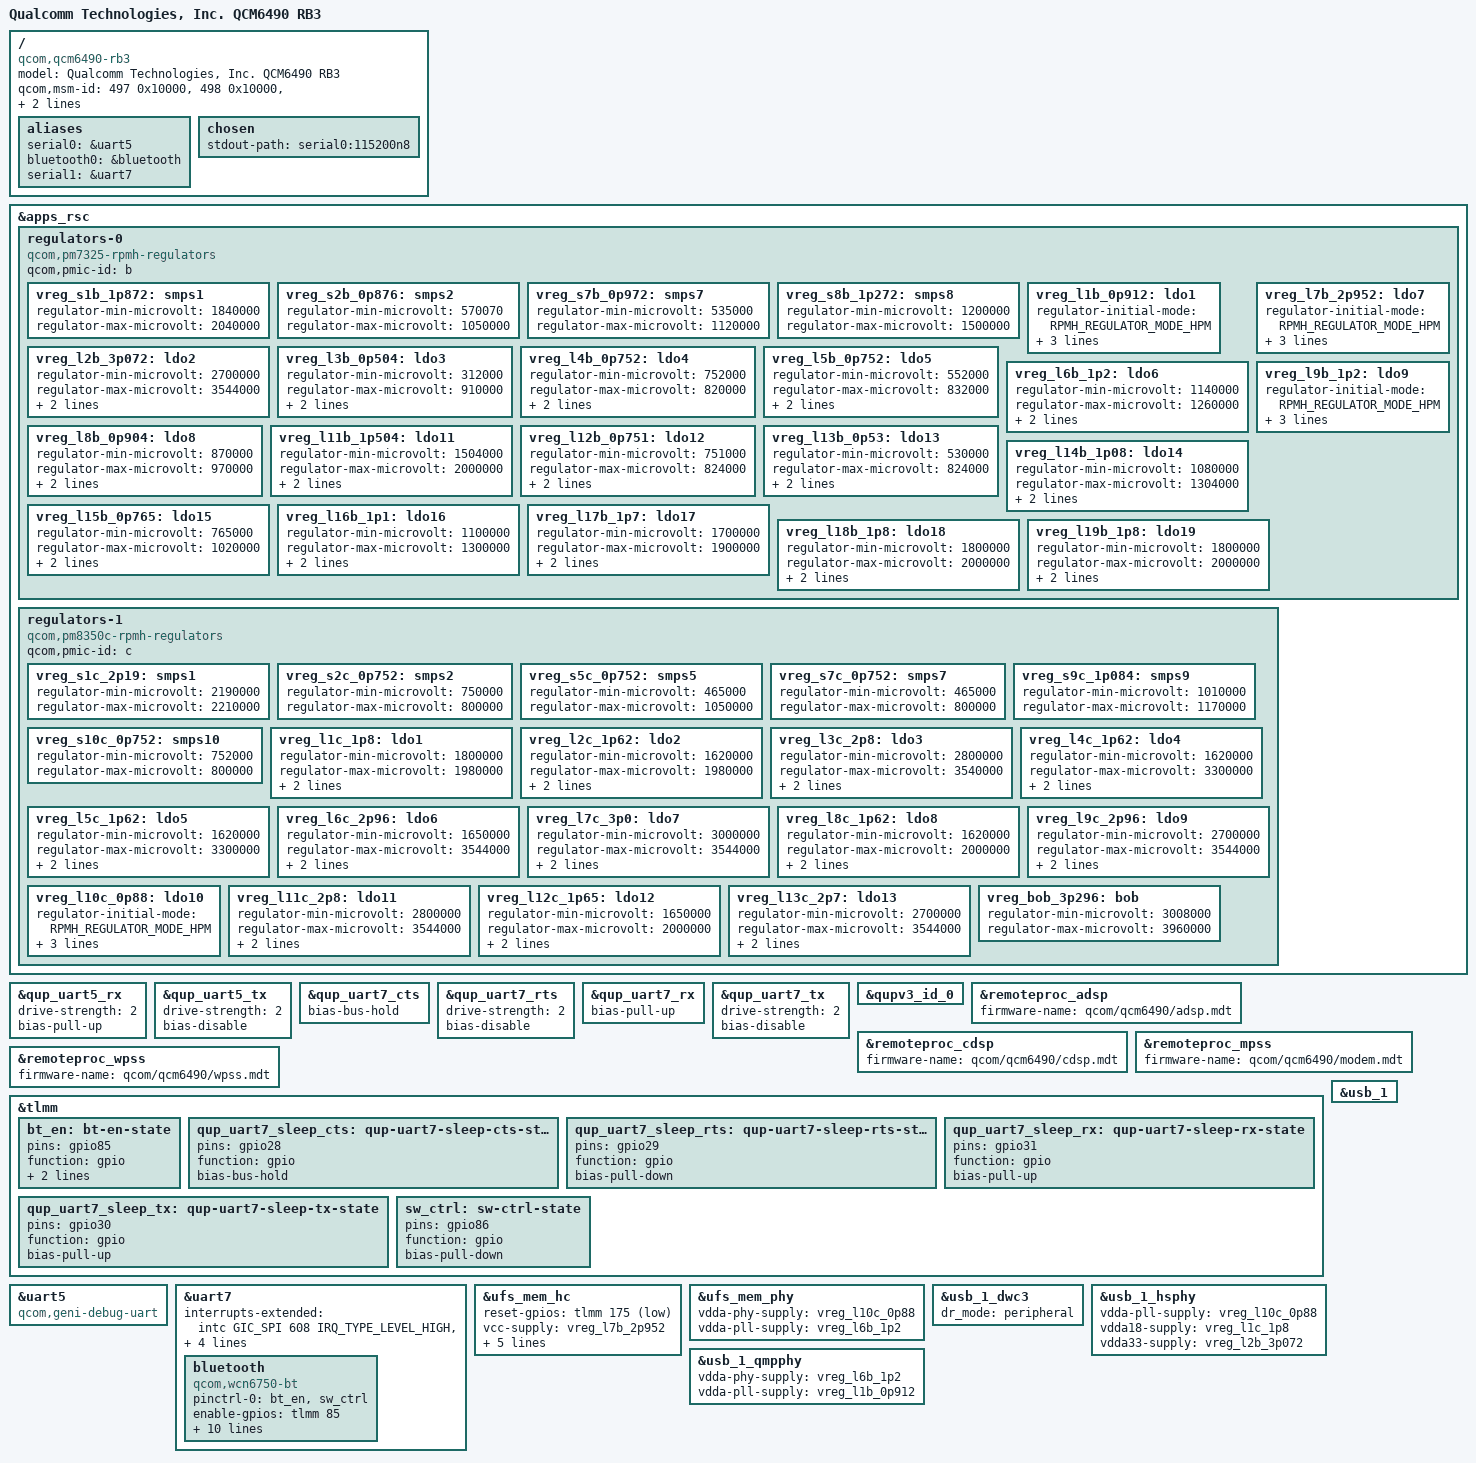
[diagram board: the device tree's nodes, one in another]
// SPDX-License-Identifier: BSD-3-Clause
/*
 * Copyright (c) 2023 Qualcomm Innovation Center, Inc. All rights reserved.
 */

/dts-v1/;

/* PM7250B is configured to use SID8/9 */
#define PM7250B_SID 8
#define PM7250B_SID1 9

#include <dt-bindings/pinctrl/qcom,pmic-gpio.h>
#include <dt-bindings/regulator/qcom,rpmh-regulator.h>
#include "qcm6490.dtsi"
#include "pm7250b.dtsi"
#include "pm7325.dtsi"
#include "pm8350c.dtsi"
#include "pmk8350.dtsi"

/ {
	model = "Qualcomm Technologies, Inc. QCM6490 RB3";
	compatible = "qcom,qcm6490-rb3", "qcom,qcm6490";

	/* This will be deprecated soon */
	qcom,msm-id = <497 0x10000>, <498 0x10000>, <475 0x10000>, <515 0x10000>;
	qcom,board-id = <32 1>;

	aliases {
		serial0 = &uart5;
		bluetooth0 = &bluetooth;
		serial1 = &uart7;
	};

	chosen {
		stdout-path = "serial0:115200n8";
	};
};

&apps_rsc {
	regulators-0 {
		compatible = "qcom,pm7325-rpmh-regulators";
		qcom,pmic-id = "b";

		vreg_s1b_1p872: smps1 {
			regulator-min-microvolt = <1840000>;
			regulator-max-microvolt = <2040000>;
		};

		vreg_s2b_0p876: smps2 {
			regulator-min-microvolt = <570070>;
			regulator-max-microvolt = <1050000>;
		};

		vreg_s7b_0p972: smps7 {
			regulator-min-microvolt = <535000>;
			regulator-max-microvolt = <1120000>;
		};

		vreg_s8b_1p272: smps8 {
			regulator-min-microvolt = <1200000>;
			regulator-max-microvolt = <1500000>;
		};

		vreg_l1b_0p912: ldo1 {
			regulator-min-microvolt = <825000>;
			regulator-max-microvolt = <925000>;
			regulator-initial-mode = <RPMH_REGULATOR_MODE_HPM>;
		};

		vreg_l2b_3p072: ldo2 {
			regulator-min-microvolt = <2700000>;
			regulator-max-microvolt = <3544000>;
			regulator-initial-mode = <RPMH_REGULATOR_MODE_HPM>;
		};

		vreg_l3b_0p504: ldo3 {
			regulator-min-microvolt = <312000>;
			regulator-max-microvolt = <910000>;
			regulator-initial-mode = <RPMH_REGULATOR_MODE_HPM>;
		};

		vreg_l4b_0p752: ldo4 {
			regulator-min-microvolt = <752000>;
			regulator-max-microvolt = <820000>;
			regulator-initial-mode = <RPMH_REGULATOR_MODE_HPM>;
		};

		vreg_l5b_0p752: ldo5 {
			regulator-min-microvolt = <552000>;
			regulator-max-microvolt = <832000>;
			regulator-initial-mode = <RPMH_REGULATOR_MODE_HPM>;
		};

		vreg_l6b_1p2: ldo6 {
			regulator-min-microvolt = <1140000>;
			regulator-max-microvolt = <1260000>;
			regulator-initial-mode = <RPMH_REGULATOR_MODE_HPM>;
		};

		vreg_l7b_2p952: ldo7 {
			regulator-min-microvolt = <2400000>;
			regulator-max-microvolt = <3544000>;
			regulator-initial-mode = <RPMH_REGULATOR_MODE_HPM>;
		};

		vreg_l8b_0p904: ldo8 {
			regulator-min-microvolt = <870000>;
			regulator-max-microvolt = <970000>;
			regulator-initial-mode = <RPMH_REGULATOR_MODE_HPM>;
		};

		vreg_l9b_1p2: ldo9 {
			regulator-min-microvolt = <1200000>;
			regulator-max-microvolt = <1304000>;
			regulator-initial-mode = <RPMH_REGULATOR_MODE_HPM>;
		};

		vreg_l11b_1p504: ldo11 {
			regulator-min-microvolt = <1504000>;
			regulator-max-microvolt = <2000000>;
			regulator-initial-mode = <RPMH_REGULATOR_MODE_HPM>;
		};

		vreg_l12b_0p751: ldo12 {
			regulator-min-microvolt = <751000>;
			regulator-max-microvolt = <824000>;
			regulator-initial-mode = <RPMH_REGULATOR_MODE_HPM>;
		};

		vreg_l13b_0p53: ldo13 {
			regulator-min-microvolt = <530000>;
			regulator-max-microvolt = <824000>;
			regulator-initial-mode = <RPMH_REGULATOR_MODE_HPM>;
		};

		vreg_l14b_1p08: ldo14 {
			regulator-min-microvolt = <1080000>;
			regulator-max-microvolt = <1304000>;
			regulator-initial-mode = <RPMH_REGULATOR_MODE_HPM>;
		};

		vreg_l15b_0p765: ldo15 {
			regulator-min-microvolt = <765000>;
			regulator-max-microvolt = <1020000>;
			regulator-initial-mode = <RPMH_REGULATOR_MODE_HPM>;
		};

		vreg_l16b_1p1: ldo16 {
			regulator-min-microvolt = <1100000>;
			regulator-max-microvolt = <1300000>;
			regulator-initial-mode = <RPMH_REGULATOR_MODE_HPM>;
		};

		vreg_l17b_1p7: ldo17 {
			regulator-min-microvolt = <1700000>;
			regulator-max-microvolt = <1900000>;
			regulator-initial-mode = <RPMH_REGULATOR_MODE_HPM>;
		};

		vreg_l18b_1p8: ldo18 {
			regulator-min-microvolt = <1800000>;
			regulator-max-microvolt = <2000000>;
			regulator-initial-mode = <RPMH_REGULATOR_MODE_HPM>;
		};

		vreg_l19b_1p8: ldo19 {
			regulator-min-microvolt = <1800000>;
			regulator-max-microvolt = <2000000>;
			regulator-initial-mode = <RPMH_REGULATOR_MODE_HPM>;
		};
	};

	regulators-1 {
		compatible = "qcom,pm8350c-rpmh-regulators";
		qcom,pmic-id = "c";

		vreg_s1c_2p19: smps1 {
			regulator-min-microvolt = <2190000>;
			regulator-max-microvolt = <2210000>;
		};

		vreg_s2c_0p752: smps2 {
			regulator-min-microvolt = <750000>;
			regulator-max-microvolt = <800000>;
		};

		vreg_s5c_0p752: smps5 {
			regulator-min-microvolt = <465000>;
			regulator-max-microvolt = <1050000>;
		};

		vreg_s7c_0p752: smps7 {
			regulator-min-microvolt = <465000>;
			regulator-max-microvolt = <800000>;
		};

		vreg_s9c_1p084: smps9 {
			regulator-min-microvolt = <1010000>;
			regulator-max-microvolt = <1170000>;
		};

		vreg_s10c_0p752:smps10 {
			regulator-min-microvolt = <752000>;
			regulator-max-microvolt = <800000>;
		};

		vreg_l1c_1p8: ldo1 {
			regulator-min-microvolt = <1800000>;
			regulator-max-microvolt = <1980000>;
			regulator-initial-mode = <RPMH_REGULATOR_MODE_HPM>;
		};

		vreg_l2c_1p62: ldo2 {
			regulator-min-microvolt = <1620000>;
			regulator-max-microvolt = <1980000>;
			regulator-initial-mode = <RPMH_REGULATOR_MODE_HPM>;
		};

		vreg_l3c_2p8: ldo3 {
			regulator-min-microvolt = <2800000>;
			regulator-max-microvolt = <3540000>;
			regulator-initial-mode = <RPMH_REGULATOR_MODE_HPM>;
		};

		vreg_l4c_1p62: ldo4 {
			regulator-min-microvolt = <1620000>;
			regulator-max-microvolt = <3300000>;
			regulator-initial-mode = <RPMH_REGULATOR_MODE_HPM>;
		};

		vreg_l5c_1p62: ldo5 {
			regulator-min-microvolt = <1620000>;
			regulator-max-microvolt = <3300000>;
			regulator-initial-mode = <RPMH_REGULATOR_MODE_HPM>;
		};

		vreg_l6c_2p96: ldo6 {
			regulator-min-microvolt = <1650000>;
			regulator-max-microvolt = <3544000>;
			regulator-initial-mode = <RPMH_REGULATOR_MODE_HPM>;
		};

		vreg_l7c_3p0: ldo7 {
			regulator-min-microvolt = <3000000>;
			regulator-max-microvolt = <3544000>;
			regulator-initial-mode = <RPMH_REGULATOR_MODE_HPM>;
		};

		vreg_l8c_1p62: ldo8 {
			regulator-min-microvolt = <1620000>;
			regulator-max-microvolt = <2000000>;
			regulator-initial-mode = <RPMH_REGULATOR_MODE_HPM>;
		};

		vreg_l9c_2p96: ldo9 {
			regulator-min-microvolt = <2700000>;
			regulator-max-microvolt = <3544000>;
			regulator-initial-mode = <RPMH_REGULATOR_MODE_HPM>;
		};

		vreg_l10c_0p88:ldo10 {
			regulator-min-microvolt = <720000>;
			regulator-max-microvolt = <1050000>;
			regulator-initial-mode = <RPMH_REGULATOR_MODE_HPM>;
		};

		vreg_l11c_2p8: ldo11 {
			regulator-min-microvolt = <2800000>;
			regulator-max-microvolt = <3544000>;
			regulator-initial-mode = <RPMH_REGULATOR_MODE_HPM>;
		};

		vreg_l12c_1p65: ldo12 {
			regulator-min-microvolt = <1650000>;
			regulator-max-microvolt = <2000000>;
			regulator-initial-mode = <RPMH_REGULATOR_MODE_HPM>;
		};

		vreg_l13c_2p7: ldo13 {
			regulator-min-microvolt = <2700000>;
			regulator-max-microvolt = <3544000>;
			regulator-initial-mode = <RPMH_REGULATOR_MODE_HPM>;
		};

		vreg_bob_3p296: bob {
			regulator-min-microvolt = <3008000>;
			regulator-max-microvolt = <3960000>;
		};
	};
};

&qup_uart5_rx {
	drive-strength = <2>;
	bias-pull-up;
};

&qup_uart5_tx {
	drive-strength = <2>;
	bias-disable;
};

&qup_uart7_cts {
	/*
	 * Configure a bias-bus-hold on CTS to lower power
	 * usage when Bluetooth is turned off. Bus hold will
	 * maintain a low power state regardless of whether
	 * the Bluetooth module drives the pin in either
	 * direction or leaves the pin fully unpowered.
	 */
	bias-bus-hold;
};

&qup_uart7_rts {
	/* We'll drive RTS, so no pull */
	drive-strength = <2>;
	bias-disable;
};

&qup_uart7_rx {
	/*
	 * Configure a pull-up on RX. This is needed to avoid
	 * garbage data when the TX pin of the Bluetooth module is
	 * in tri-state (module powered off or not driving the
	 * signal yet).
	 */
	bias-pull-up;
};

&qup_uart7_tx {
	/* We'll drive TX, so no pull */
	drive-strength = <2>;
	bias-disable;
};

&qupv3_id_0 {
	status = "okay";
};

&remoteproc_adsp {
	firmware-name = "qcom/qcm6490/adsp.mdt";
	status = "okay";
};

&remoteproc_cdsp {
	firmware-name = "qcom/qcm6490/cdsp.mdt";
	status = "okay";
};

&remoteproc_mpss {
	firmware-name = "qcom/qcm6490/modem.mdt";
	status = "okay";
};

&remoteproc_wpss {
	firmware-name = "qcom/qcm6490/wpss.mdt";
	status = "okay";
};

&tlmm {
	bt_en: bt-en-state {
		pins = "gpio85";
		function = "gpio";
		output-low;
		bias-disable;
	};

	qup_uart7_sleep_cts: qup-uart7-sleep-cts-state {
		pins = "gpio28";
		function = "gpio";
		/*
		 * Configure a bias-bus-hold on CTS to lower power
		 * usage when Bluetooth is turned off. Bus hold will
		 * maintain a low power state regardless of whether
		 * the Bluetooth module drives the pin in either
		 * direction or leaves the pin fully unpowered.
		 */
		bias-bus-hold;
	};

	qup_uart7_sleep_rts: qup-uart7-sleep-rts-state {
		pins = "gpio29";
		function = "gpio";
		/*
		 * Configure pull-down on RTS. As RTS is active low
		 * signal, pull it low to indicate the BT SoC that it
		 * can wakeup the system anytime from suspend state by
		 * pulling RX low (by sending wakeup bytes).
		 */
		bias-pull-down;
	};

	qup_uart7_sleep_rx: qup-uart7-sleep-rx-state {
		pins = "gpio31";
		function = "gpio";
		/*
		 * Configure a pull-up on RX. This is needed to avoid
		 * garbage data when the TX pin of the Bluetooth module
		 * is floating which may cause spurious wakeups.
		 */
		bias-pull-up;
	};

	qup_uart7_sleep_tx: qup-uart7-sleep-tx-state {
		pins = "gpio30";
		function = "gpio";
		/*
		 * Configure pull-up on TX when it isn't actively driven
		 * to prevent BT SoC from receiving garbage during sleep.
		 */
		bias-pull-up;
	};

	sw_ctrl: sw-ctrl-state {
		pins = "gpio86";
		function = "gpio";
		bias-pull-down;
	};
};

&uart5 {
	compatible = "qcom,geni-debug-uart";
	status = "okay";
};

&uart7 {
	status = "okay";
	/delete-property/interrupts;
	interrupts-extended = <&intc GIC_SPI 608 IRQ_TYPE_LEVEL_HIGH>,
				<&tlmm 31 IRQ_TYPE_EDGE_FALLING>;
	pinctrl-names = "default", "sleep";
	pinctrl-1 = <&qup_uart7_sleep_cts>, <&qup_uart7_sleep_rts>,
			<&qup_uart7_sleep_tx>, <&qup_uart7_sleep_rx>;

	bluetooth: bluetooth {
		compatible = "qcom,wcn6750-bt";
		pinctrl-names = "default";
		pinctrl-0 = <&bt_en>, <&sw_ctrl>;
		enable-gpios = <&tlmm 85 GPIO_ACTIVE_HIGH>;
		swctrl-gpios = <&tlmm 86 GPIO_ACTIVE_HIGH>;
		vddaon-supply = <&vreg_s7b_0p972>;
		vddbtcxmx-supply = <&vreg_s7b_0p972>;
		vddrfacmn-supply = <&vreg_s7b_0p972>;
		vddrfa0p8-supply = <&vreg_s7b_0p972>;
		vddrfa1p7-supply = <&vreg_s1b_1p872>;
		vddrfa1p2-supply = <&vreg_s8b_1p272>;
		vddrfa2p2-supply = <&vreg_s1c_2p19>;
		vddasd-supply = <&vreg_l11c_2p8>;
		max-speed = <3200000>;
	};
};

&ufs_mem_hc {
	reset-gpios = <&tlmm 175 GPIO_ACTIVE_LOW>;
	vcc-supply = <&vreg_l7b_2p952>;
	vcc-max-microamp = <800000>;
	vccq-supply = <&vreg_l9b_1p2>;
	vccq-max-microamp = <900000>;
	vccq2-supply = <&vreg_l9b_1p2>;
	vccq2-max-microamp = <900000>;

	status = "okay";
};

&ufs_mem_phy {
	vdda-phy-supply = <&vreg_l10c_0p88>;
	vdda-pll-supply = <&vreg_l6b_1p2>;

	status = "okay";
};

&usb_1 {
	status = "okay";
};

&usb_1_dwc3 {
	dr_mode = "peripheral";
};

&usb_1_hsphy {
	vdda-pll-supply = <&vreg_l10c_0p88>;
	vdda18-supply = <&vreg_l1c_1p8>;
	vdda33-supply = <&vreg_l2b_3p072>;

	status = "okay";
};

&usb_1_qmpphy {
	vdda-phy-supply = <&vreg_l6b_1p2>;
	vdda-pll-supply = <&vreg_l1b_0p912>;

	status = "okay";
};

&vreg_l1b_0p912 {
	/delete-property/regulator-min-microvolt;
	/delete-property/regulator-max-microvolt;
	regulator-allow-set-load;
	regulator-allowed-modes = <RPMH_REGULATOR_MODE_LPM RPMH_REGULATOR_MODE_HPM>;
};

&vreg_l7b_2p952 {
	/delete-property/regulator-min-microvolt;
	/delete-property/regulator-max-microvolt;
	regulator-allow-set-load;
	regulator-allowed-modes = <RPMH_REGULATOR_MODE_LPM RPMH_REGULATOR_MODE_HPM>;
};

&vreg_l9b_1p2 {
	/delete-property/regulator-min-microvolt;
	/delete-property/regulator-max-microvolt;
	regulator-allow-set-load;
	regulator-allowed-modes = <RPMH_REGULATOR_MODE_LPM RPMH_REGULATOR_MODE_HPM>;
};

&vreg_l10c_0p88 {
	/delete-property/regulator-min-microvolt;
	/delete-property/regulator-max-microvolt;
	regulator-allow-set-load;
	regulator-allowed-modes = <RPMH_REGULATOR_MODE_LPM RPMH_REGULATOR_MODE_HPM>;
};
